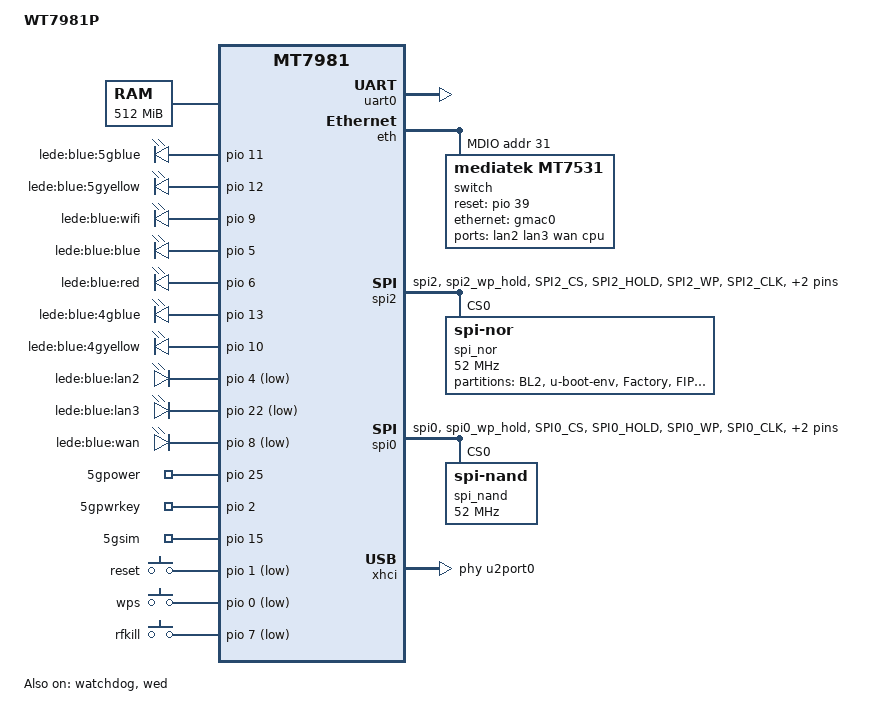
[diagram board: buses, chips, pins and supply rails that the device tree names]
/dts-v1/;
#include "mt7981.dtsi"

#include <dt-bindings/input/input.h>

/ {
	model = "WT7981P";
	compatible = "WT7981P";
	chosen {
		bootargs = "console=ttyS0,115200n1 loglevel=8  \
				earlycon=uart8250,mmio32,0x11002000";
	};

	memory {
		// fpga ddr2: 128MB*2
		reg = <0 0x40000000 0 0x20000000>;
	};

	gpio-leds {
		compatible = "gpio-leds";

		5gblue {
			label = "lede:blue:5gblue";
			gpios = <&pio 11 0>;
			linux,default-trigger = "none";
			default-state = "off";
		};

		5gyellow {
			label = "lede:blue:5gyellow";
			gpios = <&pio 12 0>;
			linux,default-trigger = "none";
			default-state = "off";
		};

		wifi {
			label = "lede:blue:wifi";
			gpios = <&pio 9 0>;
			linux,default-trigger = "none";
			default-state = "off";
		};

		blue {
			label = "lede:blue:blue";
			gpios = <&pio 5 0>;
			linux,default-trigger = "none";
			default-state = "off";
		};

		red {
			label = "lede:blue:red";
			gpios = <&pio 6 0>;
			linux,default-trigger = "none";
			default-state = "off";
		};

		4gblue {
			label = "lede:blue:4gblue";
			gpios = <&pio 13 0>;
			linux,default-trigger = "none";
			default-state = "off";
		};

		4gyellow {
			label = "lede:blue:4gyellow";
			gpios = <&pio 10 0>;
			linux,default-trigger = "none";
			default-state = "off";
		};

		lan2 {
			label = "lede:blue:lan2";
			gpios = <&pio 4 1>;
			linux,default-trigger = "none";
			default-state = "off";
		};

		lan3 {
			label = "lede:blue:lan3";
			gpios = <&pio 22 1>;
			linux,default-trigger = "none";
			default-state = "off";
		};

		wan {
			label = "lede:blue:wan";
			gpios = <&pio 8 1>;
			linux,default-trigger = "none";
			default-state = "off";
		};
	};

	gpio-export {
		compatible = "gpio-export";
		5gpower {
			gpio-export,name = "5gpower";
			gpio-export,output = <0>; // OUT_INIT_LOW
			gpios = <&pio 25 0>;    // GPIO 25, ACTIVE_LOW
		};

		5gpwrkey {
			gpio-export,name = "5gpwrkey";
			gpio-export,output = <0>; // OUT_INIT_LOW
			gpios = <&pio 2 0>;    // GPIO 2, ACTIVE_LOW
		};

		5gsim {
			gpio-export,name = "5gsim";
			gpio-export,output = <1>; // OUT_INIT_LOW
			gpios = <&pio 15 0>;    // GPIO 15, ACTIVE_LOW
		};

	};

	gpio-keys {
		compatible = "gpio-keys";
		#address-cells = <1>;
		#size-cells = <0>;
		poll-interval = <20>;

		reset {
			label = "reset";
			gpios = <&pio 1 1>;
			linux,code = <KEY_RESTART>;
		};

		wps {
			label = "wps";
			gpios = <&pio 0 1>;
			linux,code = <KEY_WPS_BUTTON>;
		};

		rfkill {
			label = "rfkill";
			gpios = <&pio 7 1>;
			linux,code = <KEY_RFKILL>;
		};
	};

	nmbm_spim_nand {
		compatible = "generic,nmbm";

		#address-cells = <1>;
		#size-cells = <1>;

		lower-mtd-device = <&spi_nand>;
		forced-create;

		partitions {
			compatible = "fixed-partitions";
			#address-cells = <1>;
			#size-cells = <1>;

			partition@0 {
				label = "ubi";
				reg = <0x00000 0x3800000>;
			};

			partition@4000000 {
				label = "ubi2";
				reg = <0x3800000 0x3800000>;
			};
		};
	};
};

&uart0 {
	status = "okay";
};

&watchdog {
	status = "okay";
};

&eth {
        status = "okay";

        gmac0: mac@0 {
                compatible = "mediatek,eth-mac";
                reg = <0>;
                phy-mode = "2500base-x";

                fixed-link {
                        speed = <2500>;
                        full-duplex;
                        pause;
                };
        };

        mdio: mdio-bus {
                #address-cells = <1>;
                #size-cells = <0>;

		switch@0 {
                        compatible = "mediatek,mt7531";
                        reg = <31>;
                        reset-gpios = <&pio 39 0>;

                        ports {
                                #address-cells = <1>;
                                #size-cells = <0>;

                                port@1 {
                                        reg = <1>;
                                        label = "lan2";
                                };

                                port@2 {
                                        reg = <2>;
                                        label = "lan3";
                                };

                        	port@3 {
                                	reg = <3>;
	                                label = "wan";
        	                };

                                port@6 {
                                        reg = <6>;
                                        label = "cpu";
                                        ethernet = <&gmac0>;
                                        phy-mode = "2500base-x";

                                        fixed-link {
                                                speed = <2500>;
                                                full-duplex;
                                                pause;
                                        };
                                };
                        };
                };
        };
};

&hnat {
	mtketh-wan = "wan";
	mtketh-lan = "lan";
	mtketh-max-gmac = <1>;
	status = "disabled";
};

&spi2 {
	pinctrl-names = "default";
	pinctrl-0 = <&spi2_flash_pins>;
	status = "okay";
	spi_nor@0 {
		#address-cells = <1>;
		#size-cells = <1>;
		compatible = "jedec,spi-nor";
		spi-cal-enable;
		spi-cal-mode = "read-data";
		spi-cal-datalen = <7>;
		spi-cal-data = /bits/ 8 <
			0x53 0x46 0x5F 0x42 0x4F 0x4F 0x54>; /* SF_BOOT */
		spi-cal-addrlen = <1>;
		spi-cal-addr = /bits/ 32 <0x0>;
		reg = <0>;
		spi-max-frequency = <52000000>;
		spi-tx-bus-width = <4>;
		spi-rx-bus-width = <4>;

		partition@00000 {
			label = "BL2";
			reg = <0x00000 0x0040000>;
		};
		partition@40000 {
			label = "u-boot-env";
			reg = <0x40000 0x0010000>;
		};
		partition@50000 {
			label = "Factory";
			reg = <0x50000 0x00B0000>;
		};
		partition@100000 {
			label = "FIP";
			reg = <0x100000 0x0200000>;
		};
		partition@300000 {
			label = "woem";
			reg = <0x300000 0x10000>;
		};
		partition@310000 {
			label = "wtinfo";
			reg = <0x310000 0x10000>;
		};
		partition@320000 {
			label = "nvram";
			reg = <0x320000 0x10000>;
		};
	};
};

&spi0 {
	pinctrl-names = "default";
	pinctrl-0 = <&spi0_flash_pins>;
	status = "okay";
	spi_nand: spi_nand@0 {
		#address-cells = <1>;
		#size-cells = <1>;
		compatible = "spi-nand";
		reg = <0>;
		spi-max-frequency = <52000000>;
		spi-tx-bus-width = <4>;
		spi-rx-bus-width = <4>;
	};
};

&pio {
	spic_pins: spi1-pins {
		mux {
			function = "spi";
			groups = "spi1_1";
		};
	};

	spi2_flash_pins: spi2-pins {
		mux {
			function = "spi";
			groups = "spi2", "spi2_wp_hold";
		};

		conf-pu {
			pins = "SPI2_CS", "SPI2_HOLD", "SPI2_WP";
			drive-strength = <MTK_DRIVE_8mA>;
			bias-pull-up = <MTK_PUPD_SET_R1R0_11>;
		};

		conf-pd {
			pins = "SPI2_CLK", "SPI2_MOSI", "SPI2_MISO";
			drive-strength = <MTK_DRIVE_8mA>;
			bias-pull-down = <MTK_PUPD_SET_R1R0_11>;
		};
	};

	spi0_flash_pins: spi0-pins {
		mux {
			function = "spi";
			groups = "spi0", "spi0_wp_hold";
		};

		conf-pu {
			pins = "SPI0_CS", "SPI0_HOLD", "SPI0_WP";
			drive-strength = <MTK_DRIVE_8mA>;
			bias-pull-up = <MTK_PUPD_SET_R1R0_11>;
		};

		conf-pd {
			pins = "SPI0_CLK", "SPI0_MOSI", "SPI0_MISO";
			drive-strength = <MTK_DRIVE_8mA>;
			bias-pull-down = <MTK_PUPD_SET_R1R0_11>;
		};
	};
};

&xhci {
	mediatek,u3p-dis-msk = <0x0>;
	phys = <&u2port0 PHY_TYPE_USB2>,
	       <&u3port0 PHY_TYPE_USB3>;
        status = "okay";
};

&wed {
	dy_txbm_enable = "true";
	dy_txbm_budget = <8>;
	txbm_init_sz = <8>;
	txbm_max_sz = <32>;
	status = "okay";
};
